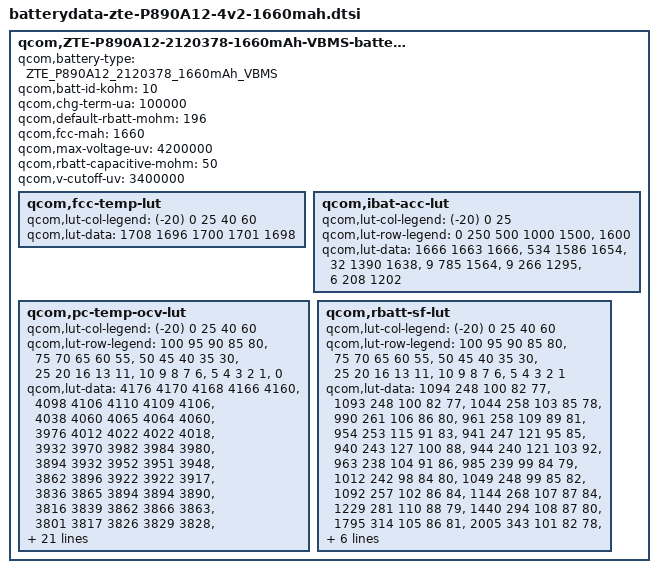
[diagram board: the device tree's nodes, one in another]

qcom,ZTE-P890A12-2120378-1660mAh-VBMS-batterydata {
	qcom,battery-type = "ZTE_P890A12_2120378_1660mAh_VBMS";
	qcom,batt-id-kohm = <10>;
	qcom,chg-term-ua = <100000>;
	qcom,default-rbatt-mohm = <196>;
	qcom,fcc-mah = <1660>;
	qcom,max-voltage-uv = <4200000>;
	qcom,rbatt-capacitive-mohm = <50>;
	qcom,v-cutoff-uv = <3400000>;

	qcom,fcc-temp-lut {
		qcom,lut-col-legend = <(-20) 0 25 40 60>;
		qcom,lut-data = <1708 1696 1700 1701 1698>;
	};

	qcom,ibat-acc-lut {
		qcom,lut-col-legend = <(-20) 0 25>;
		qcom,lut-row-legend = <0 250 500 1000 1500>,
					<1600>;
		qcom,lut-data = <1666 1663 1666>,
				<534 1586 1654>,
				<32 1390 1638>,
				<9 785 1564>,
				<9 266 1295>,
				<6 208 1202>;
	};

	qcom,pc-temp-ocv-lut {
		qcom,lut-col-legend = <(-20) 0 25 40 60>;
		qcom,lut-row-legend = <100 95 90 85 80>,
					<75 70 65 60 55>,
					<50 45 40 35 30>,
					<25 20 16 13 11>,
					<10 9 8 7 6>,
					<5 4 3 2 1>,
					<0>;
		qcom,lut-data = <4176 4170 4168 4166 4160>,
				<4098 4106 4110 4109 4106>,
				<4038 4060 4065 4064 4060>,
				<3976 4012 4022 4022 4018>,
				<3932 3970 3982 3984 3980>,
				<3894 3932 3952 3951 3948>,
				<3862 3896 3922 3922 3917>,
				<3836 3865 3894 3894 3890>,
				<3816 3839 3862 3866 3863>,
				<3801 3817 3826 3829 3828>,
				<3788 3800 3803 3802 3801>,
				<3777 3786 3788 3788 3786>,
				<3765 3778 3777 3776 3774>,
				<3753 3770 3770 3768 3765>,
				<3739 3762 3764 3759 3753>,
				<3724 3748 3755 3746 3734>,
				<3703 3725 3734 3726 3713>,
				<3682 3702 3705 3698 3686>,
				<3664 3688 3680 3673 3662>,
				<3646 3680 3675 3669 3659>,
				<3636 3676 3674 3668 3657>,
				<3624 3670 3671 3666 3655>,
				<3610 3666 3668 3663 3652>,
				<3594 3660 3665 3659 3648>,
				<3574 3650 3658 3652 3639>,
				<3546 3629 3640 3631 3612>,
				<3507 3590 3596 3586 3564>,
				<3448 3528 3532 3522 3498>,
				<3356 3434 3444 3437 3410>,
				<3216 3290 3316 3308 3262>,
				<3000 3000 3000 3000 3000>;
	};

	qcom,rbatt-sf-lut {
		qcom,lut-col-legend = <(-20) 0 25 40 60>;
		qcom,lut-row-legend = <100 95 90 85 80>,
					<75 70 65 60 55>,
					<50 45 40 35 30>,
					<25 20 16 13 11>,
					<10 9 8 7 6>,
					<5 4 3 2 1>;
		qcom,lut-data = <1094 248 100 82 77>,
				<1093 248 100 82 77>,
				<1044 258 103 85 78>,
				<990 261 106 86 80>,
				<961 258 109 89 81>,
				<954 253 115 91 83>,
				<941 247 121 95 85>,
				<940 243 127 100 88>,
				<944 240 121 103 92>,
				<963 238 104 91 86>,
				<985 239 99 84 79>,
				<1012 242 98 84 80>,
				<1049 248 99 85 82>,
				<1092 257 102 86 84>,
				<1144 268 107 87 84>,
				<1229 281 110 88 79>,
				<1440 294 108 87 80>,
				<1795 314 105 86 81>,
				<2005 343 101 82 78>,
				<2329 353 100 83 79>,
				<2624 375 102 85 80>,
				<2959 407 105 86 81>,
				<3354 450 109 89 83>,
				<3812 505 113 92 85>,
				<4402 574 118 94 86>,
				<5253 666 119 91 83>,
				<6797 781 118 91 84>,
				<9405 940 124 94 87>,
				<16596 1260 142 105 100>,
				<33192 2520 198 139 128>;
	};
};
